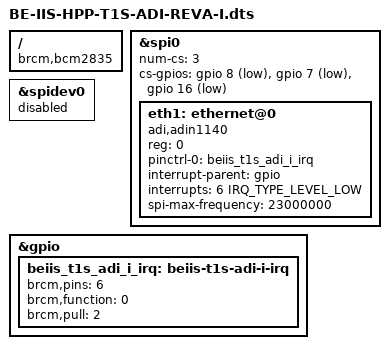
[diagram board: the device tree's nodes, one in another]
// SPDX-License-Identifier: GPL-2.0-or-later
// BE-IIS-HPP-T1S-ADI-REVA, HAT++ position I

/dts-v1/;
/plugin/;

#include <dt-bindings/interrupt-controller/irq.h>
#include <dt-bindings/gpio/gpio.h>

/ {
    compatible = "brcm,bcm2835", "brcm,bcm2711", "brcm,bcm2712";

    fragment@0 {
        target = <&spi0>;
        __overlay__ {
            #address-cells = <1>;
            #size-cells = <0>;
            status = "okay";

            num-cs = <3>;
            cs-gpios =
                <&gpio 8 GPIO_ACTIVE_LOW>,
                <&gpio 7 GPIO_ACTIVE_LOW>,
                <&gpio 16 GPIO_ACTIVE_LOW>;

            eth1: ethernet@0 {
                compatible = "adi,adin1140", "adi,ad3306";
                reg = <0>;
                pinctrl-names = "default";
                pinctrl-0 = <&beiis_t1s_adi_i_irq>;
                interrupt-parent = <&gpio>;
                interrupts = <6 IRQ_TYPE_LEVEL_LOW>;
                spi-max-frequency = <23000000>;
                status = "okay";
            };
        };
    };

    fragment@1 {
        target = <&spidev0>;
        __overlay__ { status = "disabled"; };
    };

    fragment@2 {
        target = <&gpio>;
        __overlay__ {
            beiis_t1s_adi_i_irq: beiis-t1s-adi-i-irq {
                brcm,pins = <6>;
                brcm,function = <0>;
                brcm,pull = <2>;
            };
        };
    };

    __overrides__ {
        speed = <&eth1>, "spi-max-frequency:0";
    };
};
